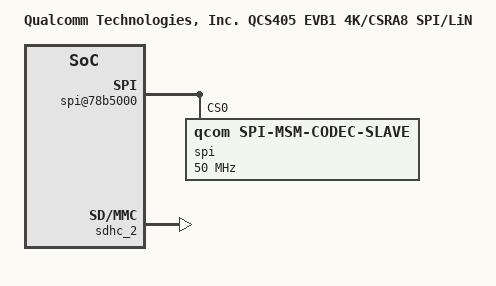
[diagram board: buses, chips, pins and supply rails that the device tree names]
/*
 * Copyright (c) 2018-2019, The Linux Foundation. All rights reserved.
 *
 * This program is free software; you can redistribute it and/or modify
 * it under the terms of the GNU General Public License version 2 and
 * only version 2 as published by the Free Software Foundation.
 *
 * This program is distributed in the hope that it will be useful,
 * but WITHOUT ANY WARRANTY; without even the implied warranty of
 * MERCHANTABILITY or FITNESS FOR A PARTICULAR PURPOSE.  See the
 * GNU General Public License for more details.
 */

/dts-v1/;

#include "qcs405.dtsi"
#include "qcs405-csra8-audio-overlay.dtsi"
#include "qcs405-geni-ir-overlay.dtsi"
#include "qcs405-linear-pca9956.dtsi"

/ {
	model = "Qualcomm Technologies, Inc. QCS405 EVB1 4K/CSRA8 SPI/LiN";
	compatible = "qcom,qcs405-iot", "qcom,qcs405", "qcom,iot";
	qcom,board-id = <0x080020 0x1>;
};

&soc {
	spi@78b5000 {
		status = "ok";
		spi@0 {
			compatible = "qcom,spi-msm-codec-slave";
			reg = <0>;
			spi-max-frequency = <50000000>;
		};
	};
};

&sdhc_2 {
	/delete-property/ qcom,devfreq,freq-table;
	/delete-property/ cd-gpios;

	qcom,clk-rates = <400000 20000000 25000000
				50000000 100000000>;
	/* VDD is an external regulator eLDO5 */
	vdd-io-supply = <&pms405_l6>;
	qcom,vdd-io-voltage-level = <1800000 1800000>;
	post-power-on-delay-ms = <100>;

	qcom,core_3_0v_support;
	qcom,nonremovable;

	pinctrl-names = "active", "sleep";
	pinctrl-0 = <&sdc2_clk_on  &sdc2_cmd_on &sdc2_data_on
		&sdc2_wlan_on4>;
	pinctrl-1 = <&sdc2_clk_off &sdc2_cmd_off &sdc2_data_off
		&sdc2_wlan_off4>;

	status = "ok";
};
